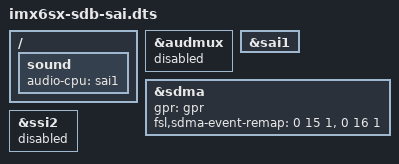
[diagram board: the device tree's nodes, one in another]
#include "imx6sx-sdb.dts"
/ {
	sound {
		audio-cpu = <&sai1>;
	};
};
&audmux {
	status = "disabled";
};
&sai1 {
	status = "okay";
};
&sdma {
	gpr = <&gpr>;
	fsl,sdma-event-remap = <0 15 1>, <0 16 1>;
};
&ssi2 {
	status = "disabled";
};
